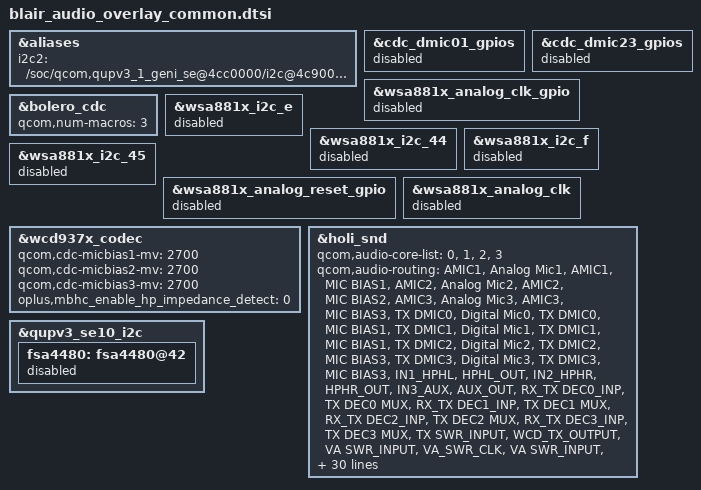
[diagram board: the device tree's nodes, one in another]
/* blair-audio-overlay.dtsi */
/* #ifdef OPLUS_ARCH_EXTENDS */
&aliases {
	i2c2 = "/soc/qcom,qupv3_1_geni_se@4cc0000/i2c@4c90000";
};


&cdc_dmic01_gpios {
	status = "disabled";
};

&cdc_dmic23_gpios {
	status = "disabled";
};

&wsa881x_analog_clk_gpio {
	status = "disabled";
};

&bolero_cdc {
	qcom,num-macros = <3>;
};

&wsa881x_i2c_e {
	status = "disabled";
};

&wsa881x_i2c_44 {
	status = "disabled";
};

&wsa881x_i2c_f {
	status = "disabled";
};

&wsa881x_i2c_45 {
	status = "disabled";
};

&wsa881x_analog_reset_gpio {
	status = "disabled";
};

&wsa881x_analog_clk {
	status = "disabled";
};

&wcd937x_codec {
	qcom,cdc-micbias1-mv = <2700>;
	qcom,cdc-micbias2-mv = <2700>;
	qcom,cdc-micbias3-mv = <2700>;
	oplus,mbhc_enable_hp_impedance_detect = <0>;
};

&holi_snd {
	qcom,audio-core-list = <0>, <1>, <2>, <3>;
	qcom,audio-routing =
		"AMIC1", "Analog Mic1",
		"AMIC1", "MIC BIAS1",
		"AMIC2", "Analog Mic2",
		"AMIC2", "MIC BIAS2",
		"AMIC3", "Analog Mic3",
		"AMIC3", "MIC BIAS3",
		"TX DMIC0", "Digital Mic0",
		"TX DMIC0", "MIC BIAS1",
		"TX DMIC1", "Digital Mic1",
		"TX DMIC1", "MIC BIAS1",
		"TX DMIC2", "Digital Mic2",
		"TX DMIC2", "MIC BIAS3",
		"TX DMIC3", "Digital Mic3",
		"TX DMIC3", "MIC BIAS3",
		"IN1_HPHL", "HPHL_OUT",
		"IN2_HPHR", "HPHR_OUT",
		"IN3_AUX", "AUX_OUT",
		"RX_TX DEC0_INP", "TX DEC0 MUX",
		"RX_TX DEC1_INP", "TX DEC1 MUX",
		"RX_TX DEC2_INP", "TX DEC2 MUX",
		"RX_TX DEC3_INP", "TX DEC3 MUX",
		"TX SWR_INPUT", "WCD_TX_OUTPUT",
		"VA SWR_INPUT", "VA_SWR_CLK",
		"VA SWR_INPUT", "WCD_TX_OUTPUT",
		"VA_AIF1 CAP", "VA_SWR_CLK",
		"VA_AIF2 CAP", "VA_SWR_CLK",
		"VA_AIF3 CAP", "VA_SWR_CLK",
		"VA DMIC0", "Digital Mic0",
		"VA DMIC1", "Digital Mic1",
		"VA DMIC2", "Digital Mic2",
		"VA DMIC3", "Digital Mic3",
		"VA DMIC4", "Digital Mic4",
		"VA DMIC5", "Digital Mic5",
		"VA DMIC0", "VA MIC BIAS1",
		"VA DMIC1", "VA MIC BIAS1",
		"VA DMIC2", "VA MIC BIAS3",
		"VA DMIC3", "VA MIC BIAS3";
	qcom,msm-mbhc-moist-cfg = <1>, <3>, <0>;
	qcom,msm-mbhc-usbc-audio-supported = <0>;
	qcom,msm-mbhc-hphl-swh = <1>;
	qcom,msm-mbhc-gnd-swh = <1>;
	qcom,msm-mbhc-hs-mic-max-threshold-mv = <2600>;
	qcom,msm-mbhc-hs-mic-min-threshold-mv = <75>;
	qcom,mi2s-audio-intf = <0>;
	qcom,auxpcm-audio-intf = <0>;
	qcom,cdc-dmic01-gpios;
	qcom,cdc-dmic23-gpios;

	asoc-codec  = <&stub_codec>, <&bolero_cdc>,
			  <&wcd937x_codec>;
	asoc-codec-names = "msm-stub-codec.1", "bolero-codec",
			   "wcd937x_codec";
	qcom,wsa-max-devs = <0>;

	oplus,mbhc-check-cross-conn = <0>;
	oplus,mbhc-headset-micbias-alwayon = <1>;
	qcom,afe-rxtx-lb = <1>;
	oplus,mbhc-check-irq-en = <1>;
	oplus,mbhc-headset-detect-mode = <0>;
	oplus,speaker-pa = "sia81xx";
};

&qupv3_se10_i2c {
	status = "ok";
	fsa4480: fsa4480@42 {
		status = "disabled";
	};
};
/* OPLUS_ARCH_EXTENDS */
